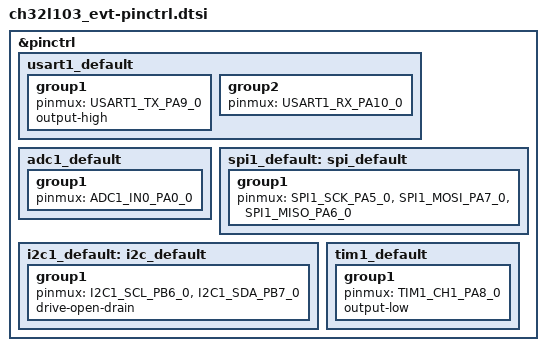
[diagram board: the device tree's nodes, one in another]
/*
 * Copyright (c) 2026 Scott King
 *
 * SPDX-License-Identifier: Apache-2.0
 */

#include <zephyr/dt-bindings/pinctrl/ch32l103-pinctrl.h>

&pinctrl {
	usart1_default: usart1_default {
		group1 {
			pinmux = <USART1_TX_PA9_0>;
			output-high;
		};

		group2 {
			pinmux = <USART1_RX_PA10_0>;
		};
	};

	adc1_default: adc1_default {
		group1 {
			pinmux = <ADC1_IN0_PA0_0>;
		};
	};

	spi1_default: spi_default {
		group1 {
			pinmux = <SPI1_SCK_PA5_0>, <SPI1_MOSI_PA7_0>, <SPI1_MISO_PA6_0>;
		};
	};

	i2c1_default: i2c_default {
		group1 {
			pinmux = <I2C1_SCL_PB6_0>, <I2C1_SDA_PB7_0>;
			drive-open-drain;
		};
	};

	tim1_default: tim1_default {
		group1 {
			pinmux = <TIM1_CH1_PA8_0>;
			output-low;
		};
	};
};
